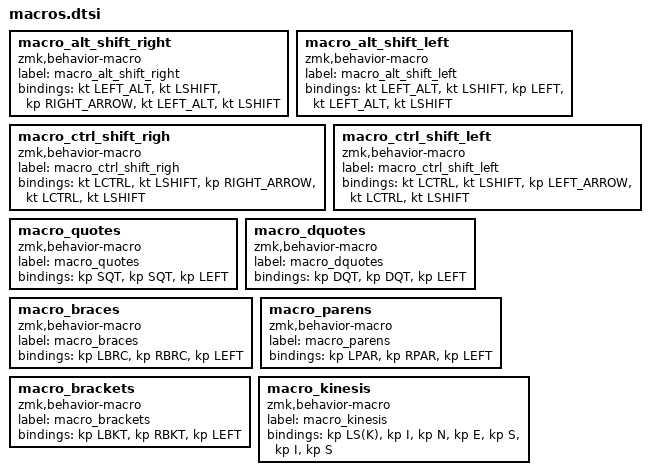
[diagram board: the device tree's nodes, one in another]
macro_alt_shift_right: macro_alt_shift_right{
compatible = "zmk,behavior-macro";
label = "macro_alt_shift_right";
#binding-cells = <0>;
bindings = <&kt LEFT_ALT>, <&kt LSHIFT>, <&kp RIGHT_ARROW>, <&kt LEFT_ALT>, <&kt LSHIFT>;
};
macro_alt_shift_left: macro_alt_shift_left{
compatible = "zmk,behavior-macro";
label = "macro_alt_shift_left";
#binding-cells = <0>;
bindings = <&kt LEFT_ALT>, <&kt LSHIFT>, <&kp LEFT>, <&kt LEFT_ALT>, <&kt LSHIFT>;
};
macro_ctrl_shift_righ: macro_ctrl_shift_righ{
compatible = "zmk,behavior-macro";
label = "macro_ctrl_shift_righ";
#binding-cells = <0>;
bindings = <&kt LCTRL>, <&kt LSHIFT>, <&kp RIGHT_ARROW>, <&kt LCTRL>, <&kt LSHIFT>;
};
macro_ctrl_shift_left: macro_ctrl_shift_left{
compatible = "zmk,behavior-macro";
label = "macro_ctrl_shift_left";
#binding-cells = <0>;
bindings = <&kt LCTRL>, <&kt LSHIFT>, <&kp LEFT_ARROW>, <&kt LCTRL>, <&kt LSHIFT>;
};
macro_quotes: macro_quotes{
compatible = "zmk,behavior-macro";
label = "macro_quotes";
#binding-cells = <0>;
bindings = <&kp SQT>, <&kp SQT>, <&kp LEFT>;
};
macro_dquotes: macro_dquotes{
compatible = "zmk,behavior-macro";
label = "macro_dquotes";
#binding-cells = <0>;
bindings = <&kp DQT>, <&kp DQT>, <&kp LEFT>;
};
macro_braces: macro_braces{
compatible = "zmk,behavior-macro";
label = "macro_braces";
#binding-cells = <0>;
bindings = <&kp LBRC>, <&kp RBRC>, <&kp LEFT>;
};
macro_parens: macro_parens{
compatible = "zmk,behavior-macro";
label = "macro_parens";
#binding-cells = <0>;
bindings = <&kp LPAR>, <&kp RPAR>, <&kp LEFT>;
};
macro_brackets: macro_brackets{
compatible = "zmk,behavior-macro";
label = "macro_brackets";
#binding-cells = <0>;
bindings = <&kp LBKT>, <&kp RBKT>, <&kp LEFT>;
};
macro_kinesis: macro_kinesis{
compatible = "zmk,behavior-macro";
label = "macro_kinesis";
#binding-cells = <0>;
bindings = <&kp LS(K)>, <&kp I>, <&kp N>, <&kp E>, <&kp S>, <&kp I>, <&kp S>;
};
